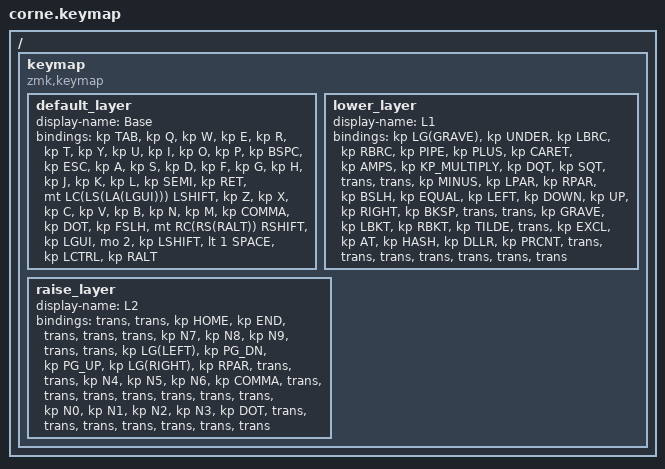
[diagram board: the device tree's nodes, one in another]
/*
 * Copyright (c) 2020 The ZMK Contributors
 *
 * SPDX-License-Identifier: MIT
 */

#include <behaviors.dtsi>
#include <dt-bindings/zmk/bt.h>
#include <dt-bindings/zmk/keys.h>

/ {
    keymap {
        compatible = "zmk,keymap";

        default_layer {
            display-name = "Base";
            bindings = <

                // Top row
                &kp TAB
                &kp Q
                &kp W
                &kp E
                &kp R
                &kp T

                &kp Y
                &kp U
                &kp I
                &kp O
                &kp P
                &kp BSPC

                // Middle row
                &kp ESC
                &kp A
                &kp S
                &kp D
                &kp F
                &kp G

                &kp H
                &kp J
                &kp K
                &kp L
                &kp SEMI
                &kp RET

                // Bottom row
                &mt LC(LS(LA(LGUI))) LSHIFT  // Hyper
                &kp Z
                &kp X
                &kp C
                &kp V
                &kp B

                &kp N
                &kp M
                &kp COMMA
                &kp DOT
                &kp FSLH
                &mt RC(RS(RALT)) RSHIFT  // Meh

                // Thumb row
                &kp LGUI
                &mo 2
                &kp LSHIFT

                &lt 1 SPACE
                &kp LCTRL
                &kp RALT
            >;
        };

        lower_layer {
            display-name = "L1";
            bindings = <

                // Top row
                &kp LG(GRAVE)  // Cmd+` for window switching within same app
                &kp UNDER
                &kp LBRC
                &kp RBRC
                &kp PIPE
                &kp PLUS

                &kp CARET
                &kp AMPS
                &kp KP_MULTIPLY
                &kp DQT
                &kp SQT
                &trans

                // Middle row
                &trans
                &kp MINUS
                &kp LPAR
                &kp RPAR
                &kp BSLH
                &kp EQUAL

                &kp LEFT
                &kp DOWN
                &kp UP
                &kp RIGHT
                &kp BKSP
                &trans

                // Bottom row
                &trans
                &kp GRAVE
                &kp LBKT
                &kp RBKT
                &kp TILDE
                &trans

                &kp EXCL
                &kp AT
                &kp HASH
                &kp DLLR
                &kp PRCNT
                &trans

                // Thumb row
                &trans
                &trans
                &trans

                &trans
                &trans
                &trans
            >;
        };

        raise_layer {
            display-name = "L2";
            bindings = <

                // Top row
                &trans
                &trans
                &kp HOME
                &kp END
                &trans
                &trans

                &trans
                &kp N7
                &kp N8
                &kp N9
                &trans
                &trans

                // Middle row
                &kp LG(LEFT)  // Cmd+Left, beginning of line on Mac
                &kp PG_DN
                &kp PG_UP
                &kp LG(RIGHT)  // Cmd+Right, end of line on Mac
                &kp RPAR
                &trans

                &trans
                &kp N4
                &kp N5
                &kp N6
                &kp COMMA
                &trans

                // Bottom row
                &trans
                &trans
                &trans
                &trans
                &trans
                &trans

                &kp N0
                &kp N1
                &kp N2
                &kp N3
                &kp DOT
                &trans

                // Thumb row
                &trans
                &trans
                &trans

                &trans
                &trans
                &trans
            >;
        };
    };
};
